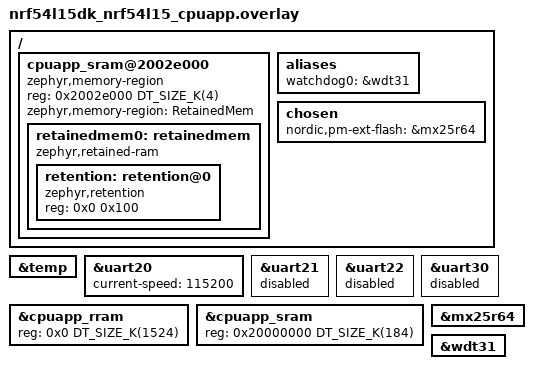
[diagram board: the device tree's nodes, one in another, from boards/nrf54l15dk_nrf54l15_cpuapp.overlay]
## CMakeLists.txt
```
cmake_minimum_required(VERSION 3.20.0)

find_package(Zephyr HINTS $ENV{ZEPHYR_BASE})

project(nrf54_soil)

# Enable GNU STD support for Matter to use
include(${ZEPHYR_CONNECTEDHOMEIP_MODULE_DIR}/config/nrfconnect/app/enable-gnu-std.cmake)

# Matter data model generation
include(${ZEPHYR_CONNECTEDHOMEIP_MODULE_DIR}/src/app/chip_data_model.cmake)

target_include_directories(app PRIVATE
    src
)

target_sources(app PRIVATE
    src/main.cpp
    src/retained.cpp
)
```

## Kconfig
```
mainmenu "nRF54 Deep Sleep Example Configuration"

config APP_WAKEUP_INTERVAL_SEC
	int "Wakeup interval (seconds)"
	default 300
	help
	  Time between wakeups.

config GRTC_WAKEUP_ENABLE
	bool "Use GRTC to wake up device from system off"
	default y
	help
	  Enable system off wakeup from GRTC.

source "Kconfig.zephyr"
```

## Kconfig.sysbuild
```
# nRF54 Deep Sleep Example - Sysbuild Configuration

#### Bootloader
choice BOOTLOADER
	default BOOTLOADER_MCUBOOT
endchoice

if BOOTLOADER_MCUBOOT

config PM_OVERRIDE_EXTERNAL_DRIVER_CHECK
	default y

# MCUboot padding size
config PM_MCUBOOT_PAD
	default 0x800

# Use overwrite-only mode (simpler, no swap)
choice MCUBOOT_MODE
	default MCUBOOT_MODE_OVERWRITE_ONLY
endchoice

endif # BOOTLOADER_MCUBOOT

source "share/sysbuild/Kconfig"
```

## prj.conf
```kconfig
# nRF54 Soil Moisture Sensor - Debug Configuration
# Development build with full logging

# Application features
CONFIG_APP_WAKEUP_INTERVAL_SEC=5

# GRTC timer for wakeup from System OFF
CONFIG_NRF_GRTC_TIMER=y

# RAM retention in System OFF
CONFIG_RETAINED_MEM=y
CONFIG_RETAINED_MEM_MUTEX_FORCE_DISABLE=y
CONFIG_RETENTION=y
CONFIG_CRC=y

# Hardware info for reset cause detection
CONFIG_HWINFO=y

# Power Management
CONFIG_PM_DEVICE=y
CONFIG_PM_DEVICE_RUNTIME=y

# System Off (deep sleep)
CONFIG_POWEROFF=y

# Memory footprint
CONFIG_HEAP_MEM_POOL_SIZE=1024
CONFIG_IDLE_STACK_SIZE=256

# Minimal libc
CONFIG_MINIMAL_LIBC=y

# Console for debugging
CONFIG_CONSOLE=y
CONFIG_UART_CONSOLE=y

# Configure logging
# CONFIG_LOG=y
# CONFIG_LOG_MODE_IMMEDIATE=y
# CONFIG_LOG_FUNC_NAME_PREFIX_DBG=n

# Disable shell for cleaner output
# CONFIG_SHELL=y
# CONFIG_SHELL_LOG_BACKEND=y

# Size optimizations
CONFIG_SIZE_OPTIMIZATIONS=y
CONFIG_LTO=y
```

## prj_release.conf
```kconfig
# nRF54 Deep Sleep Example - Release Configuration Overrides
# Optimized to reduce power consumption

# Application features
CONFIG_APP_WAKEUP_INTERVAL_SEC=300

# Disable all logging
CONFIG_LOG=n

# Disable console/UART
CONFIG_CONSOLE=n
CONFIG_UART_CONSOLE=n
CONFIG_SERIAL=n

# Disable assertions
CONFIG_ASSERT=n
CONFIG_ASSERT_VERBOSE=n

# Disable debug features
CONFIG_DEBUG=n
CONFIG_DEBUG_INFO=n
CONFIG_THREAD_NAME=n
CONFIG_PRINTK=n
CONFIG_BOOT_BANNER=n

# Disable shell
CONFIG_SHELL=n
CONFIG_CHIP_LIB_SHELL=n
```

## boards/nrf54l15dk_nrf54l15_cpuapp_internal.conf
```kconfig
# Enable LTO to decrease the flash usage.
CONFIG_LTO=y
CONFIG_ISR_TABLES_LOCAL_DECLARATION=y
```

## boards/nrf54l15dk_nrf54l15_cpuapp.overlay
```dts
/ {
	/* Retained RAM for state across System OFF */
	cpuapp_sram@2002e000 {
		compatible = "zephyr,memory-region", "mmio-sram";
		reg = <0x2002e000 DT_SIZE_K(4)>;
		zephyr,memory-region = "RetainedMem";
		status = "okay";

		retainedmem0: retainedmem {
			compatible = "zephyr,retained-ram";
			status = "okay";
			#address-cells = <1>;
			#size-cells = <1>;

			retention: retention@0 {
				compatible = "zephyr,retention";
				status = "okay";
				reg = <0x0 0x100>;
			};
		};
	};

	aliases {
		watchdog0 = &wdt31;
	};

	chosen {
		nordic,pm-ext-flash = &mx25r64;
	};
};

/* Enable internal temperature sensor */
&temp {
	status = "okay";
};

/* Keep UART20 for console (it's the default console) */
&uart20 {
	status = "okay";
	current-speed = <115200>;
};

/* Disable unused peripherals to save power */
&uart21 {
	status = "disabled";
};

&uart22 {
	status = "disabled";
};

&uart30 {
	status = "disabled";
};

// restore full RRAM and SRAM space - by default some parts are dedicated to FLRP
&cpuapp_rram {
	reg = <0x0 DT_SIZE_K(1524)>;
};

&cpuapp_sram {
	/* Shrink SRAM size to avoid overlap with retained memory region */
	reg = <0x20000000 DT_SIZE_K(184)>;
	ranges = <0x0 0x20000000 0x2e000>;
};

&mx25r64 {
	status = "okay";
};

&wdt31 {
	status = "okay";
};
```

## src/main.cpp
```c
#include <zephyr/kernel.h>
#include <zephyr/sys/printk.h>
#include <zephyr/drivers/hwinfo.h>
#include <zephyr/sys/poweroff.h>
#include <zephyr/device.h>
#include <zephyr/pm/device.h>
#include "retained.h"

#if defined(CONFIG_GRTC_WAKEUP_ENABLE)
#include <zephyr/drivers/timer/nrf_grtc_timer.h>
#define WAKEUP_INTERVAL_SEC CONFIG_APP_WAKEUP_INTERVAL_SEC
#endif

int main()
{
	uint32_t reset_cause;
	bool valid_retained;
	int err;
	const struct device *const cons = DEVICE_DT_GET(DT_CHOSEN(zephyr_console));

	/* Small delay for console to initialize */
	k_sleep(K_MSEC(100));

	/* Get reset cause */
	hwinfo_get_reset_cause(&reset_cause);

	/* Check if retained data is valid */
	valid_retained = retained_validate();

	if (valid_retained && (reset_cause & RESET_CLOCK)) {
		printk("=== Wakeup from deep sleep ===\n");
		retained.measurement_count++;
	} else {
		printk("=== Cold boot ===\n");
		/* Initialize retained data */
		memset(&retained, 0, sizeof(retained));
		retained.measurement_count = 0;
		retained.boot_count = 1;
	}

	/* Print the incrementing counter */
	printk("Counter: %u\n", retained.measurement_count);

	/* Update retained data */
	retained_update();

#if defined(CONFIG_GRTC_WAKEUP_ENABLE)
	/* Setup wakeup timer */
	err = z_nrf_grtc_wakeup_prepare(WAKEUP_INTERVAL_SEC * USEC_PER_SEC);
	if (err < 0) {
		printk("Failed to prepare GRTC wakeup (err = %d)\n", err);
		return err;
	}

	/* Enter System OFF (deep sleep) */
	printk("Entering deep sleep for %d seconds...\n", WAKEUP_INTERVAL_SEC);
#else
	printk("Entering deep sleep (no wakeup configured)...\n");
#endif

	/* Suspend console to allow deep sleep */
	err = pm_device_action_run(cons, PM_DEVICE_ACTION_SUSPEND);
	if (err < 0) {
		printk("Could not suspend console (%d)\n", err);
	}

	hwinfo_clear_reset_cause();
	sys_poweroff();

	/* Should never reach here */
	return 0;
}
```
